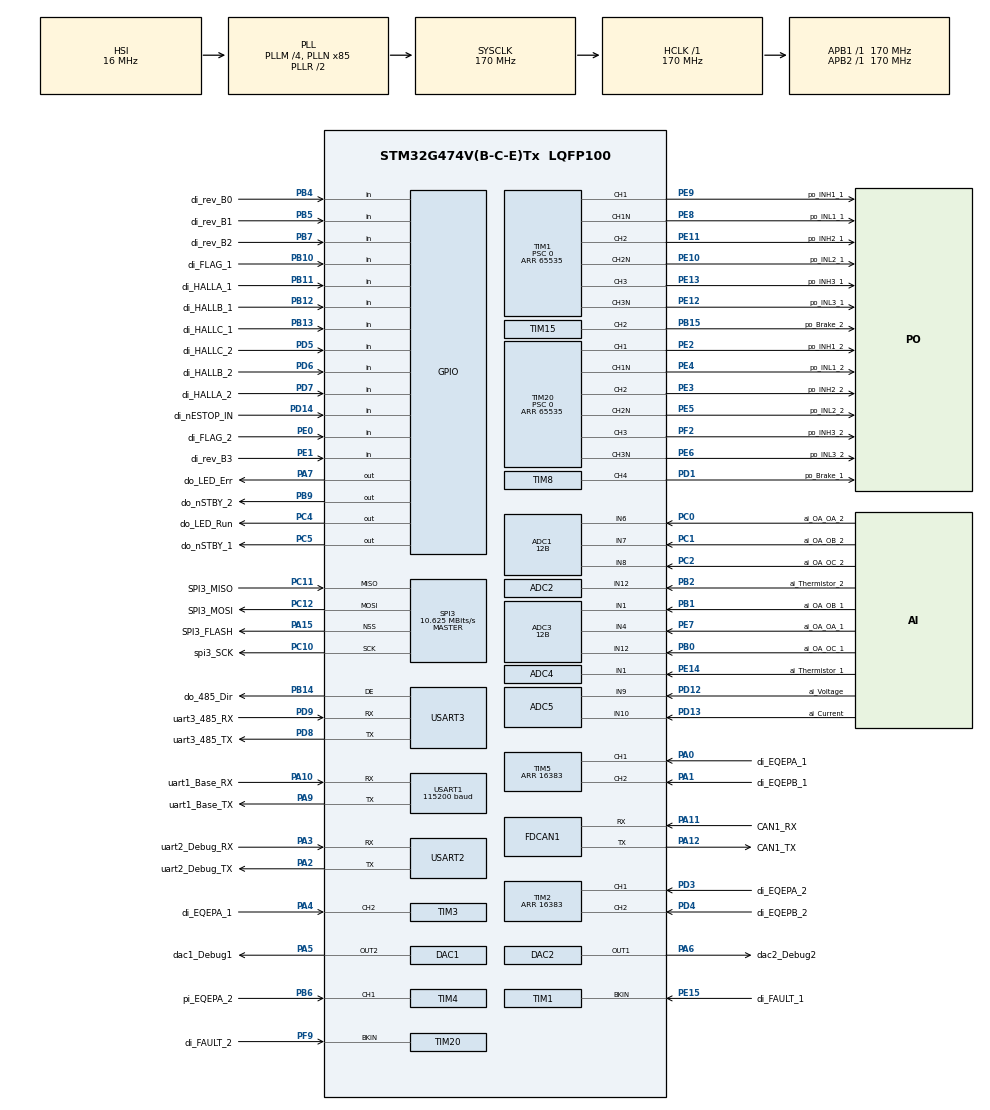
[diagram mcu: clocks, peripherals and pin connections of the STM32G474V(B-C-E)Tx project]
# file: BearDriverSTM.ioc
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ADC1.ClockPrescaler=ADC_CLOCK_ASYNC_DIV4
ADC1.ContinuousConvMode=DISABLE
ADC1.DMAContinuousRequests=DISABLE
ADC1.DataAlign=ADC_DATAALIGN_RIGHT
ADC1.DiscontinuousConvMode=DISABLE
ADC1.EOCSelection=ADC_EOC_SINGLE_CONV
ADC1.EnableAnalogWatchDog1=false
ADC1.EnableAnalogWatchDog2=false
ADC1.EnableAnalogWatchDog3=false
ADC1.EnableInjectedConversion=ENABLE
ADC1.EnableRegularConversion=DISABLE
ADC1.ExternalTrigInjecConv=ADC_EXTERNALTRIGINJEC_T1_TRGO
ADC1.ExternalTrigInjecConvEdge=ADC_EXTERNALTRIGINJECCONV_EDGE_RISING
ADC1.InjNumberOfConversion=2
ADC1.InjectedChannel-1\#ChannelInjectedConversion=ADC_CHANNEL_6
ADC1.InjectedChannel-2\#ChannelInjectedConversion=ADC_CHANNEL_7
ADC1.InjectedConvMode=None
ADC1.InjectedOffset-1\#ChannelInjectedConversion=0
ADC1.InjectedOffset-2\#ChannelInjectedConversion=0
ADC1.InjectedOffsetNumber-1\#ChannelInjectedConversion=ADC_OFFSET_NONE
ADC1.InjectedOffsetNumber-2\#ChannelInjectedConversion=ADC_OFFSET_NONE
ADC1.InjectedRank-1\#ChannelInjectedConversion=1
ADC1.InjectedRank-2\#ChannelInjectedConversion=2
ADC1.InjectedSamplingTime-1\#ChannelInjectedConversion=ADC_SAMPLETIME_6CYCLES_5
ADC1.InjectedSamplingTime-2\#ChannelInjectedConversion=ADC_SAMPLETIME_6CYCLES_5
ADC1.LowPowerAutoWait=DISABLE
ADC1.Overrun=ADC_OVR_DATA_PRESERVED
ADC1.Resolution=ADC_RESOLUTION_12B
ADC1.ScanConvMode=ADC_SCAN_ENABLE
ADC1.master=1
ADC2.Channel-0\#ChannelRegularConversion=ADC_CHANNEL_12
ADC2.ClockPrescaler=ADC_CLOCK_ASYNC_DIV4
ADC2.ContinuousConvMode=DISABLE
ADC2.DMAContinuousRequests=DISABLE
ADC2.DataAlign=ADC_DATAALIGN_RIGHT
ADC2.DiscontinuousConvMode=DISABLE
ADC2.EOCSelection=ADC_EOC_SINGLE_CONV
ADC2.EnableAnalogWatchDog1=false
ADC2.EnableAnalogWatchDog2=false
ADC2.EnableAnalogWatchDog3=false
ADC2.EnableInjectedConversion=ENABLE
ADC2.EnableRegularConversion=ENABLE
ADC2.ExternalTrigConv=ADC_SOFTWARE_START
ADC2.ExternalTrigConvEdge=ADC_EXTERNALTRIGCONVEDGE_NONE
ADC2.ExternalTrigInjecConv=ADC_EXTERNALTRIGINJEC_T1_TRGO
ADC2.ExternalTrigInjecConvEdge=ADC_EXTERNALTRIGINJECCONV_EDGE_RISING
ADC2.InjNumberOfConversion=1
ADC2.InjectedChannel-1\#ChannelInjectedConversion=ADC_CHANNEL_12
ADC2.InjectedConvMode=None
ADC2.InjectedOffset-1\#ChannelInjectedConversion=0
ADC2.InjectedOffsetNumber-1\#ChannelInjectedConversion=ADC_OFFSET_NONE
ADC2.InjectedRank-1\#ChannelInjectedConversion=1
ADC2.InjectedSamplingTime-1\#ChannelInjectedConversion=ADC_SAMPLETIME_6CYCLES_5
ADC2.LowPowerAutoWait=DISABLE
ADC2.NbrOfConversion=1
ADC2.OffsetNumber-0\#ChannelRegularConversion=ADC_OFFSET_NONE
ADC2.Overrun=ADC_OVR_DATA_PRESERVED
ADC2.Rank-0\#ChannelRegularConversion=1
ADC2.Resolution=ADC_RESOLUTION_12B
ADC2.SamplingTime-0\#ChannelRegularConversion=ADC_SAMPLETIME_47CYCLES_5
ADC2.ScanConvMode=ADC_SCAN_DISABLE
ADC2.master=1
ADC3.ClockPrescaler=ADC_CLOCK_ASYNC_DIV4
ADC3.ContinuousConvMode=DISABLE
ADC3.DMAContinuousRequests=DISABLE
ADC3.DataAlign=ADC_DATAALIGN_RIGHT
ADC3.DiscontinuousConvMode=DISABLE
ADC3.EOCSelection=ADC_EOC_SINGLE_CONV
ADC3.EnableAnalogWatchDog1=false
ADC3.EnableAnalogWatchDog2=false
ADC3.EnableAnalogWatchDog3=false
ADC3.EnableInjectedConversion=ENABLE
ADC3.EnableRegularConversion=DISABLE
ADC3.ExternalTrigInjecConv=ADC_EXTERNALTRIGINJEC_T20_TRGO
ADC3.ExternalTrigInjecConvEdge=ADC_EXTERNALTRIGINJECCONV_EDGE_RISING
ADC3.InjNumberOfConversion=2
ADC3.InjectedChannel-1\#ChannelInjectedConversion=ADC_CHANNEL_4
ADC3.InjectedChannel-2\#ChannelInjectedConversion=ADC_CHANNEL_12
ADC3.InjectedConvMode=None
ADC3.InjectedOffset-1\#ChannelInjectedConversion=0
ADC3.InjectedOffset-2\#ChannelInjectedConversion=0
ADC3.InjectedOffsetNumber-1\#ChannelInjectedConversion=ADC_OFFSET_NONE
ADC3.InjectedOffsetNumber-2\#ChannelInjectedConversion=ADC_OFFSET_NONE
ADC3.InjectedRank-1\#ChannelInjectedConversion=1
ADC3.InjectedRank-2\#ChannelInjectedConversion=2
ADC3.InjectedSamplingTime-1\#ChannelInjectedConversion=ADC_SAMPLETIME_6CYCLES_5
ADC3.InjectedSamplingTime-2\#ChannelInjectedConversion=ADC_SAMPLETIME_6CYCLES_5
ADC3.LowPowerAutoWait=DISABLE
ADC3.Overrun=ADC_OVR_DATA_PRESERVED
ADC3.Resolution=ADC_RESOLUTION_12B
ADC3.ScanConvMode=ADC_SCAN_ENABLE
ADC3.master=1
ADC4.Channel-2\#ChannelRegularConversion=ADC_CHANNEL_1
ADC4.ClockPrescaler=ADC_CLOCK_ASYNC_DIV4
ADC4.ContinuousConvMode=DISABLE
ADC4.DMAContinuousRequests=DISABLE
ADC4.DataAlign=ADC_DATAALIGN_RIGHT
ADC4.DiscontinuousConvMode=DISABLE
ADC4.EOCSelection=ADC_EOC_SINGLE_CONV
ADC4.EnableInjectedConversion=DISABLE
ADC4.EnableRegularConversion=ENABLE
ADC4.LowPowerAutoWait=DISABLE
ADC4.NbrOfConversionFlag=1
ADC4.OffsetNumber-2\#ChannelRegularConversion=ADC_OFFSET_NONE
ADC4.Overrun=ADC_OVR_DATA_PRESERVED
ADC4.Rank-2\#ChannelRegularConversion=1
ADC4.Resolution=ADC_RESOLUTION_12B
ADC4.SamplingTime-2\#ChannelRegularConversion=ADC_SAMPLETIME_2CYCLES_5
ADC4.ScanConvMode=ADC_SCAN_DISABLE
ADC5.Channel-0\#ChannelRegularConversion=ADC_CHANNEL_9
ADC5.Channel-1\#ChannelRegularConversion=ADC_CHANNEL_10
ADC5.ClockPrescaler=ADC_CLOCK_ASYNC_DIV4
ADC5.ContinuousConvMode=DISABLE
ADC5.EOCSelection=ADC_EOC_SINGLE_CONV
ADC5.EnableRegularConversion=ENABLE
ADC5.NbrOfConversion=2
ADC5.OffsetNumber-0\#ChannelRegularConversion=ADC_OFFSET_NONE
ADC5.OffsetNumber-1\#ChannelRegularConversion=ADC_OFFSET_NONE
ADC5.Rank-0\#ChannelRegularConversion=1
ADC5.Rank-1\#ChannelRegularConversion=2
ADC5.SamplingTime-0\#ChannelRegularConversion=ADC_SAMPLETIME_47CYCLES_5
ADC5.SamplingTime-1\#ChannelRegularConversion=ADC_SAMPLETIME_47CYCLES_5
ADC5.ScanConvMode=ADC_SCAN_ENABLE
DAC1.DAC_Channel-DAC_OUT2=DAC_CHANNEL_2
DAC2.DAC_OutputBuffer=DAC_OUTPUTBUFFER_DISABLE
DAC2.DAC_Trigger=DAC_TRIGGER_SOFTWARE
FDCAN1.CalculateBaudRateNominal=3541666
FDCAN1.CalculateTimeBitNominal=282
FDCAN1.CalculateTimeQuantumNominal=94.11764705882354
IWDG.Prescaler=IWDG_PRESCALER_4
Mcu.Family=STM32G4
Mcu.Name=STM32G474V(B-C-E)Tx
Mcu.Package=LQFP100
NVIC.ADC1_2_IRQn=true\:2\:0\:true\:true\:true\:5\:true\:true\:true
NVIC.ADC3_IRQn=true\:2\:0\:true\:true\:true\:9\:true\:true\:true
NVIC.PriorityGroup=NVIC_PRIORITYGROUP_3
NVIC.TIM1_BRK_TIM15_IRQn=true\:4\:0\:true\:true\:true\:3\:true\:true\:true
NVIC.TIM1_UP_TIM16_IRQn=true\:0\:0\:false\:true\:true\:4\:true\:true\:true
NVIC.TIM20_BRK_IRQn=true\:4\:0\:true\:true\:true\:10\:true\:true\:true
NVIC.TIM20_UP_IRQn=true\:0\:0\:false\:true\:true\:11\:true\:true\:true
NVIC.TIM2_IRQn=true\:3\:0\:true\:true\:true\:6\:true\:true\:true
NVIC.TIM5_IRQn=true\:3\:0\:true\:true\:true\:12\:true\:true\:true
NVIC.USART1_IRQn=true\:3\:0\:true\:true\:true\:13\:true\:true\:true
NVIC.USART2_IRQn=true\:3\:0\:true\:true\:true\:1\:true\:true\:true
NVIC.USART3_IRQn=true\:3\:0\:true\:true\:true\:8\:true\:true\:true
PA0.GPIO_Label=di_EQEPA_1
PA0.Signal=S_TIM5_CH1
PA1.GPIO_Label=di_EQEPB_1
PA1.Signal=S_TIM5_CH2
PA10.GPIO_Label=uart1_Base_RX
PA10.Mode=Asynchronous
PA10.Signal=USART1_RX
PA11.GPIO_Label=CAN1_RX
PA11.Mode=FDCAN_Activate
PA11.Signal=FDCAN1_RX
PA12.GPIO_Label=CAN1_TX
PA12.Mode=FDCAN_Activate
PA12.Signal=FDCAN1_TX
PA13.GPIO_Label=SWDIO
PA13.Mode=Trace_Asynchronous_SW
PA13.Signal=SYS_JTMS-SWDIO
PA14.GPIO_Label=SWCLK
PA14.Mode=Trace_Asynchronous_SW
PA14.Signal=SYS_JTCK-SWCLK
PA15.GPIO_Label=SPI3_FLASH
PA15.Mode=NSS_Signal_Hard_Output
PA15.Signal=SPI3_NSS
PA2.GPIO_Label=uart2_Debug_TX
PA2.GPIO_PuPd=GPIO_PULLUP
PA2.GPIO_Speed=GPIO_SPEED_FREQ_HIGH
PA2.Mode=Asynchronous
PA2.Signal=USART2_TX
PA3.GPIO_Label=uart2_Debug_RX
PA3.GPIO_PuPd=GPIO_PULLUP
PA3.GPIO_Speed=GPIO_SPEED_FREQ_HIGH
PA3.Mode=Asynchronous
PA3.Signal=USART2_RX
PA4.GPIO_Label=di_EQEPA_1
PA4.Signal=S_TIM3_CH2
PA5.GPIO_Label=dac1_Debug1
PA5.Signal=COMP_DAC12_group
PA6.GPIO_Label=dac2_Debug2
PA6.Signal=COMP_DAC21_group
PA7.GPIO_Label=do_LED_Err
PA7.Signal=GPIO_Output
PA9.GPIO_Label=uart1_Base_TX
PA9.Mode=Asynchronous
PA9.Signal=USART1_TX
PB0.GPIO_Label=ai_OA_OC_1
PB0.Mode=IN12-Single-Ended
PB0.Signal=ADC3_IN12
PB1.GPIO_Label=ai_OA_OB_1
PB1.Mode=IN1-Single-Ended
PB1.Signal=ADC3_IN1
PB10.GPIO_Label=di_FLAG_1
PB10.GPIO_PuPd=GPIO_PULLUP
PB10.Signal=GPIO_Input
PB11.GPIO_Label=di_HALLA_1
PB11.Signal=GPIO_Input
PB12.GPIO_Label=di_HALLB_1
PB12.Signal=GPIO_Input
PB13.GPIO_Label=di_HALLC_1
PB13.Signal=GPIO_Input
PB14.GPIO_Label=do_485_Dir
PB14.Mode=Hardware Flow Control (RS485)
PB14.Signal=USART3_DE
PB15.GPIO_Label=po_Brake_2
PB15.GPIO_PuPd=GPIO_PULLDOWN
PB15.GPIO_Speed=GPIO_SPEED_FREQ_HIGH
PB15.Signal=S_TIM15_CH2
PB2.GPIO_Label=ai_Thermistor_2
PB2.Mode=IN12-Single-Ended
PB2.Signal=ADC2_IN12
PB3.GPIO_Label=SWO
PB3.Mode=Trace_Asynchronous_SW
PB3.Signal=SYS_JTDO-SWO
PB4.GPIO_Label=di_rev_B0
PB4.Signal=GPIO_Input
PB5.GPIO_Label=di_rev_B1
PB5.Signal=GPIO_Input
PB6.GPIO_Label=pi_EQEPA_2
PB6.Signal=S_TIM4_CH1
PB7.GPIO_Label=di_rev_B2
PB7.Signal=GPIO_Input
PB9.GPIO_Label=do_nSTBY_2
PB9.Signal=GPIO_Output
PC0.GPIO_Label=ai_OA_OA_2
PC0.Mode=IN6-Single-Ended
PC0.Signal=ADC1_IN6
PC1.GPIO_Label=ai_OA_OB_2
PC1.Mode=IN7-Single-Ended
PC1.Signal=ADC1_IN7
PC10.GPIO_Label=spi3_SCK
PC10.Mode=Full_Duplex_Master
PC10.Signal=SPI3_SCK
PC11.GPIO_Label=SPI3_MISO
PC11.Mode=Full_Duplex_Master
PC11.Signal=SPI3_MISO
PC12.GPIO_Label=SPI3_MOSI
PC12.Mode=Full_Duplex_Master
PC12.Signal=SPI3_MOSI
PC2.GPIO_Label=ai_OA_OC_2
PC2.Mode=IN8-Single-Ended
PC2.Signal=ADC1_IN8
PC4.GPIO_Label=do_LED_Run
PC4.Signal=GPIO_Output
PC5.GPIO_Label=do_nSTBY_1
PC5.Signal=GPIO_Output
PD1.GPIO_Label=po_Brake_1
PD1.GPIO_PuPd=GPIO_PULLDOWN
PD1.GPIO_Speed=GPIO_SPEED_FREQ_HIGH
PD1.Signal=S_TIM8_CH4
PD12.GPIO_Label=ai_Voltage
PD12.Mode=IN9-Single-Ended
PD12.Signal=ADC5_IN9
PD13.GPIO_Label=ai_Current
PD13.Mode=IN10-Single-Ended
PD13.Signal=ADC5_IN10
PD14.GPIO_Label=di_nESTOP_IN
PD14.Signal=GPIO_Input
PD3.GPIO_Label=di_EQEPA_2
PD3.Signal=S_TIM2_CH1
PD4.GPIO_Label=di_EQEPB_2
PD4.Signal=S_TIM2_CH2
PD5.GPIO_Label=di_HALLC_2
PD5.Signal=GPIO_Input
PD6.GPIO_Label=di_HALLB_2
PD6.Signal=GPIO_Input
PD7.GPIO_Label=di_HALLA_2
PD7.Signal=GPIO_Input
PD8.GPIO_Label=uart3_485_TX
PD8.Mode=Asynchronous
PD8.Signal=USART3_TX
PD9.GPIO_Label=uart3_485_RX
PD9.Mode=Asynchronous
PD9.Signal=USART3_RX
PE0.GPIO_Label=di_FLAG_2
PE0.GPIO_PuPd=GPIO_PULLUP
PE0.Signal=GPIO_Input
PE1.GPIO_Label=di_rev_B3
PE1.Signal=GPIO_Input
PE10.GPIO_Label=po_INL2_1
PE10.GPIO_PuPd=GPIO_PULLDOWN
PE10.GPIO_Speed=GPIO_SPEED_FREQ_HIGH
PE10.Mode=PWM Generation2 CH2 CH2N
PE10.Signal=TIM1_CH2N
PE11.GPIO_Label=po_INH2_1
PE11.GPIO_ModeDefaultPP=GPIO_MODE_AF_PP
PE11.GPIO_PuPd=GPIO_PULLDOWN
PE11.GPIO_Speed=GPIO_SPEED_FREQ_HIGH
PE11.Signal=S_TIM1_CH2
PE12.GPIO_Label=po_INL3_1
PE12.GPIO_ModeDefaultPP=GPIO_MODE_AF_PP
PE12.GPIO_PuPd=GPIO_PULLDOWN
PE12.GPIO_Speed=GPIO_SPEED_FREQ_HIGH
PE12.Mode=PWM Generation3 CH3 CH3N
PE12.Signal=TIM1_CH3N
PE13.GPIO_Label=po_INH3_1
PE13.GPIO_PuPd=GPIO_PULLDOWN
PE13.GPIO_Speed=GPIO_SPEED_FREQ_HIGH
PE13.Signal=S_TIM1_CH3
PE14.GPIO_Label=ai_Thermistor_1
PE14.Mode=IN1-Single-Ended
PE14.Signal=ADC4_IN1
PE15.GPIO_Label=di_FAULT_1
PE15.GPIO_PuPd=GPIO_PULLUP
PE15.Mode=Activate-Break-Input
PE15.Signal=TIM1_BKIN
PE2.GPIO_Label=po_INH1_2
PE2.GPIO_PuPd=GPIO_PULLDOWN
PE2.GPIO_Speed=GPIO_SPEED_FREQ_HIGH
PE2.Signal=S_TIM20_CH1
PE3.GPIO_Label=po_INH2_2
PE3.GPIO_PuPd=GPIO_PULLDOWN
PE3.GPIO_Speed=GPIO_SPEED_FREQ_HIGH
PE3.Signal=S_TIM20_CH2
PE4.GPIO_Label=po_INL1_2
PE4.GPIO_PuPd=GPIO_PULLDOWN
PE4.GPIO_Speed=GPIO_SPEED_FREQ_HIGH
PE4.Mode=PWM Generation1 CH1 CH1N
PE4.Signal=TIM20_CH1N
PE5.GPIO_Label=po_INL2_2
PE5.GPIO_PuPd=GPIO_PULLDOWN
PE5.GPIO_Speed=GPIO_SPEED_FREQ_HIGH
PE5.Mode=PWM Generation2 CH2 CH2N
PE5.Signal=TIM20_CH2N
PE6.GPIO_Label=po_INL3_2
PE6.GPIO_PuPd=GPIO_PULLDOWN
PE6.GPIO_Speed=GPIO_SPEED_FREQ_HIGH
PE6.Mode=PWM Generation3 CH3 CH3N
PE6.Signal=TIM20_CH3N
PE7.GPIO_Label=ai_OA_OA_1
PE7.Mode=IN4-Single-Ended
PE7.Signal=ADC3_IN4
PE8.GPIO_Label=po_INL1_1
PE8.GPIO_ModeDefaultPP=GPIO_MODE_AF_PP
PE8.GPIO_PuPd=GPIO_PULLDOWN
PE8.GPIO_Speed=GPIO_SPEED_FREQ_HIGH
PE8.Mode=PWM Generation1 CH1 CH1N
PE8.Signal=TIM1_CH1N
PE9.GPIO_Label=po_INH1_1
PE9.GPIO_ModeDefaultPP=GPIO_MODE_AF_PP
PE9.GPIO_PuPd=GPIO_PULLDOWN
PE9.GPIO_Speed=GPIO_SPEED_FREQ_HIGH
PE9.Signal=S_TIM1_CH1
PF0-OSC_IN.Mode=HSE-External-Oscillator
PF0-OSC_IN.Signal=RCC_OSC_IN
PF1-OSC_OUT.Mode=HSE-External-Oscillator
PF1-OSC_OUT.Signal=RCC_OSC_OUT
PF2.GPIO_Label=po_INH3_2
PF2.GPIO_PuPd=GPIO_PULLDOWN
PF2.GPIO_Speed=GPIO_SPEED_FREQ_HIGH
PF2.Signal=S_TIM20_CH3
PF9.GPIO_Label=di_FAULT_2
PF9.GPIO_PuPd=GPIO_PULLUP
PF9.Mode=Activate-Break-Input
PF9.Signal=TIM20_BKIN
ProjectManager.HeapSize=0x200
ProjectManager.StackSize=0x400
ProjectManager.TargetToolchain=STM32CubeIDE
RCC.ADC12CLockSelection=RCC_ADC12CLKSOURCE_PLL
RCC.ADC12Freq_Value=170000000
RCC.ADC345Freq_Value=170000000
RCC.AHBFreq_Value=170000000
RCC.APB1Freq_Value=170000000
RCC.APB1TimFreq_Value=170000000
RCC.APB2Freq_Value=170000000
RCC.APB2TimFreq_Value=170000000
RCC.CortexFreq_Value=170000000
RCC.EXTERNAL_CLOCK_VALUE=12288000
RCC.HCLKFreq_Value=170000000
RCC.HSE_VALUE=8000000
RCC.HSI48_VALUE=48000000
RCC.HSI_VALUE=16000000
RCC.LSE_VALUE=32768
RCC.PLLM=RCC_PLLM_DIV4
RCC.PLLN=85
RCC.SYSCLKFreq_VALUE=170000000
RCC.SYSCLKSource=RCC_SYSCLKSOURCE_PLLCLK
RCC.USBFreq_Value=170000000
RCC.VCOOutputFreq_Value=340000000
SH.COMP_DAC12_group.0=DAC1_OUT2,DAC_OUT2
SH.COMP_DAC21_group.0=DAC2_OUT1,DAC_OUT1
SH.S_TIM15_CH2.0=TIM15_CH2,PWM Generation2 CH2
SH.S_TIM1_CH1.0=TIM1_CH1,PWM Generation1 CH1 CH1N
SH.S_TIM1_CH2.0=TIM1_CH2,PWM Generation2 CH2 CH2N
SH.S_TIM1_CH3.0=TIM1_CH3,PWM Generation3 CH3 CH3N
SH.S_TIM20_CH1.0=TIM20_CH1,PWM Generation1 CH1 CH1N
SH.S_TIM20_CH2.0=TIM20_CH2,PWM Generation2 CH2 CH2N
SH.S_TIM20_CH3.0=TIM20_CH3,PWM Generation3 CH3 CH3N
SH.S_TIM2_CH1.0=TIM2_CH1,Encoder_Interface
SH.S_TIM2_CH2.0=TIM2_CH2,Encoder_Interface
SH.S_TIM3_CH2.0=TIM3_CH2,Input_Capture2_from_TI2
SH.S_TIM4_CH1.0=TIM4_CH1,Input_Capture1_from_TI1
SH.S_TIM5_CH1.0=TIM5_CH1,Encoder_Interface
SH.S_TIM5_CH2.0=TIM5_CH2,Encoder_Interface
SH.S_TIM8_CH4.0=TIM8_CH4,PWM Generation4 CH4
SPI3.BaudRatePrescaler=SPI_BAUDRATEPRESCALER_16
SPI3.CalculateBaudRate=10.625 MBits/s
SPI3.DataSize=SPI_DATASIZE_8BIT
SPI3.Direction=SPI_DIRECTION_2LINES
SPI3.Mode=SPI_MODE_MASTER
SPI3.VirtualNSS=VM_NSSHARD
SPI3.VirtualType=VM_MASTER
TIM1.AutoReloadPreload=TIM_AUTORELOAD_PRELOAD_DISABLE
TIM1.AutomaticOutput=TIM_AUTOMATICOUTPUT_DISABLE
TIM1.Break2Filter=3
TIM1.Break2Polarity=TIM_BREAK2POLARITY_HIGH
TIM1.Break2State=TIM_BREAK2_DISABLE
TIM1.BreakFilter=3
TIM1.BreakPolarity=TIM_BREAKPOLARITY_LOW
TIM1.BreakState=TIM_BREAK_ENABLE
TIM1.Channel=TIM_CHANNEL_4
TIM1.Channel-PWM\ Generation1\ CH1\ CH1N=TIM_CHANNEL_1
TIM1.Channel-PWM\ Generation2\ CH2\ CH2N=TIM_CHANNEL_2
TIM1.Channel-PWM\ Generation3\ CH3\ CH3N=TIM_CHANNEL_3
TIM1.Channel-PWM\ Generation4\ No\ Output=TIM_CHANNEL_4
TIM1.ClearInputSource=TIM_CLEARINPUTSOURCE_NONE
TIM1.ClockDivision=TIM_CLOCKDIVISION_DIV2
TIM1.CounterMode=TIM_COUNTERMODE_CENTERALIGNED1
TIM1.DeadTime=0
TIM1.LockLevel=TIM_LOCKLEVEL_OFF
TIM1.OC1Preload_PWM=ENABLE
TIM1.OC2Preload_PWM=ENABLE
TIM1.OC3Preload_PWM=ENABLE
TIM1.OC4Preload_PWM=ENABLE
TIM1.OCFastMode_PWM=TIM_OCFAST_DISABLE
TIM1.OCIdleState_1=TIM_OCIDLESTATE_RESET
TIM1.OCIdleState_2=TIM_OCIDLESTATE_RESET
TIM1.OCIdleState_3=TIM_OCIDLESTATE_RESET
TIM1.OCIdleState_4=TIM_OCIDLESTATE_RESET
TIM1.OCMode_PWM-PWM\ Generation1\ CH1\ CH1N=TIM_OCMODE_PWM1
TIM1.OCMode_PWM-PWM\ Generation2\ CH2\ CH2N=TIM_OCMODE_PWM1
TIM1.OCMode_PWM-PWM\ Generation3\ CH3\ CH3N=TIM_OCMODE_PWM1
TIM1.OCMode_PWM-PWM\ Generation4\ No\ Output=TIM_OCMODE_PWM2
TIM1.OCNIdleState_1=TIM_OCNIDLESTATE_RESET
TIM1.OCNIdleState_2=TIM_OCNIDLESTATE_RESET
TIM1.OCNIdleState_3=TIM_OCNIDLESTATE_RESET
TIM1.OCNPolarity_1=TIM_OCNPOLARITY_HIGH
TIM1.OCNPolarity_2=TIM_OCNPOLARITY_HIGH
TIM1.OCNPolarity_3=TIM_OCNPOLARITY_HIGH
TIM1.OCPolarity_1=TIM_OCPOLARITY_HIGH
TIM1.OCPolarity_2=TIM_OCPOLARITY_HIGH
TIM1.OCPolarity_3=TIM_OCPOLARITY_HIGH
TIM1.OCPolarity_4=TIM_OCPOLARITY_HIGH
TIM1.OffStateIDLEMode=TIM_OSSI_ENABLE
TIM1.OffStateRunMode=TIM_OSSR_ENABLE
TIM1.PeriodNoDither=65535
TIM1.Prescaler=0
TIM1.PulseNoDither_1=0
TIM1.PulseNoDither_2=0
TIM1.PulseNoDither_3=0
TIM1.PulseNoDither_4=0
TIM1.RepetitionCounter=0
TIM1.SourceBRK2DigInput=TIM_BREAKINPUTSOURCE_DISABLE
TIM1.SourceBRKDigInput=TIM_BREAKINPUTSOURCE_ENABLE
TIM1.SourceBRKDigInputPolarity=TIM_BREAKINPUTSOURCE_POLARITY_LOW
TIM1.TIM_MasterOutputTrigger=TIM_TRGO_OC4REF
TIM1.TIM_MasterOutputTrigger2=TIM_TRGO2_RESET
TIM1.TIM_MasterSlaveMode=TIM_MASTERSLAVEMODE_DISABLE
TIM1.TIM_SlaveMode=TIM_SLAVEMODE_TRIGGER
TIM15.Channel-PWM\ Generation2\ CH2=TIM_CHANNEL_2
TIM2.EncoderMode=TIM_ENCODERMODE_TI12
TIM2.IC1Filter=0
TIM2.IC1Polarity=TIM_ICPOLARITY_RISING
TIM2.IC2Filter=0
TIM2.IC2Polarity=TIM_ICPOLARITY_RISING
TIM2.PeriodNoDither=16383
TIM20.AutoReloadPreload=TIM_AUTORELOAD_PRELOAD_DISABLE
TIM20.AutomaticOutput=TIM_AUTOMATICOUTPUT_DISABLE
TIM20.Break2Filter=3
TIM20.Break2Polarity=TIM_BREAK2POLARITY_HIGH
TIM20.Break2State=TIM_BREAK2_DISABLE
TIM20.BreakFilter=3
TIM20.BreakPolarity=TIM_BREAKPOLARITY_LOW
TIM20.BreakState=TIM_BREAK_ENABLE
TIM20.Channel=TIM_CHANNEL_4
TIM20.Channel-PWM\ Generation1\ CH1\ CH1N=TIM_CHANNEL_1
TIM20.Channel-PWM\ Generation2\ CH2\ CH2N=TIM_CHANNEL_2
TIM20.Channel-PWM\ Generation3\ CH3\ CH3N=TIM_CHANNEL_3
TIM20.Channel-PWM\ Generation4\ No\ Output=TIM_CHANNEL_4
TIM20.ClearInputSource=TIM_CLEARINPUTSOURCE_NONE
TIM20.ClockDivision=TIM_CLOCKDIVISION_DIV2
TIM20.CounterMode=TIM_COUNTERMODE_CENTERALIGNED1
TIM20.DeadTime=0
TIM20.LockLevel=TIM_LOCKLEVEL_OFF
TIM20.OC1Preload_PWM=ENABLE
TIM20.OC2Preload_PWM=ENABLE
TIM20.OC3Preload_PWM=ENABLE
TIM20.OC4Preload_PWM=ENABLE
TIM20.OCFastMode_PWM=TIM_OCFAST_DISABLE
TIM20.OCIdleState_1=TIM_OCIDLESTATE_RESET
TIM20.OCIdleState_2=TIM_OCIDLESTATE_RESET
TIM20.OCIdleState_3=TIM_OCIDLESTATE_RESET
TIM20.OCIdleState_4=TIM_OCIDLESTATE_RESET
TIM20.OCMode_PWM-PWM\ Generation1\ CH1\ CH1N=TIM_OCMODE_PWM1
TIM20.OCMode_PWM-PWM\ Generation2\ CH2\ CH2N=TIM_OCMODE_PWM1
TIM20.OCMode_PWM-PWM\ Generation3\ CH3\ CH3N=TIM_OCMODE_PWM1
TIM20.OCMode_PWM-PWM\ Generation4\ No\ Output=TIM_OCMODE_PWM2
TIM20.OCNIdleState_1=TIM_OCNIDLESTATE_RESET
TIM20.OCNIdleState_2=TIM_OCNIDLESTATE_RESET
TIM20.OCNIdleState_3=TIM_OCNIDLESTATE_RESET
TIM20.OCNPolarity_1=TIM_OCNPOLARITY_HIGH
TIM20.OCNPolarity_2=TIM_OCNPOLARITY_HIGH
TIM20.OCNPolarity_3=TIM_OCNPOLARITY_HIGH
TIM20.OCPolarity_1=TIM_OCPOLARITY_HIGH
TIM20.OCPolarity_2=TIM_OCPOLARITY_HIGH
TIM20.OCPolarity_3=TIM_OCPOLARITY_HIGH
TIM20.OCPolarity_4=TIM_OCPOLARITY_HIGH
TIM20.OffStateIDLEMode=TIM_OSSI_ENABLE
TIM20.OffStateRunMode=TIM_OSSR_ENABLE
TIM20.PeriodNoDither=65535
TIM20.Prescaler=0
TIM20.PulseNoDither_1=0
TIM20.PulseNoDither_2=0
TIM20.PulseNoDither_3=0
TIM20.PulseNoDither_4=0
TIM20.RepetitionCounter=0
TIM20.SourceBRK2DigInput=TIM_BREAKINPUTSOURCE_DISABLE
TIM20.SourceBRKDigInput=TIM_BREAKINPUTSOURCE_ENABLE
TIM20.SourceBRKDigInputPolarity=TIM_BREAKINPUTSOURCE_POLARITY_LOW
TIM20.TIM_MasterOutputTrigger=TIM_TRGO_OC4REF
TIM20.TIM_MasterOutputTrigger2=TIM_TRGO2_RESET
TIM20.TIM_MasterSlaveMode=TIM_MASTERSLAVEMODE_DISABLE
TIM20.TIM_SlaveMode=TIM_SLAVEMODE_TRIGGER
TIM3.Channel-Input_Capture2_from_TI2=TIM_CHANNEL_2
TIM4.Channel-Input_Capture1_from_TI1=TIM_CHANNEL_1
TIM5.EncoderMode=TIM_ENCODERMODE_TI12
TIM5.IC1Filter=0
TIM5.IC1Polarity=TIM_ICPOLARITY_RISING
TIM5.IC2Filter=0
TIM5.IC2Polarity=TIM_ICPOLARITY_RISING
TIM5.PeriodNoDither=16383
TIM8.Channel-PWM\ Generation4\ CH4=TIM_CHANNEL_4
USART1.BaudRate=115200
USART1.VirtualMode-Asynchronous=VM_ASYNC
USART1.WordLength=WORDLENGTH_8B
USART2.VirtualMode-Asynchronous=VM_ASYNC
USART3.VirtualMode-Asynchronous=VM_ASYNC
USART3.VirtualMode-Hardware\ Flow\ Control\ (RS485)=VM_ASYNC
VP_IWDG_VS_IWDG.Mode=IWDG_Activate
VP_SYS_VS_DBSignals.Mode=DisableDeadBatterySignals
VP_TIM1_VS_no_output4.Mode=PWM Generation4 No Output
VP_TIM20_VS_no_output4.Mode=PWM Generation4 No Output
board=custom

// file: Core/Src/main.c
/* USER CODE BEGIN Header */
/**
  ******************************************************************************
  * @file           : main.c
  * @brief          : Main program body
  ******************************************************************************
  * @attention
  *
  * Copyright (c) 2026 STMicroelectronics.
  * All rights reserved.
  *
  * This software is licensed under terms that can be found in the LICENSE file
  * in the root directory of this software component.
  * If no LICENSE file comes with this software, it is provided AS-IS.
  *
  ******************************************************************************
  */
/* USER CODE END Header */
#include "main.h"
#include "adc.h"
#include "dac.h"
#include "fdcan.h"
#include "iwdg.h"
#include "spi.h"
#include "tim.h"
#include "usart.h"
#include "gpio.h"

/* USER CODE BEGIN Includes */
#include "bear_driver.h"
#include "debug.h"
/* USER CODE END Includes */

/* USER CODE BEGIN PV */
volatile uint32_t IdleLoopCount = 0;
/* USER CODE END PV */

void SystemClock_Config(void);
static void MX_NVIC_Init(void);

int main(void)
{

  /* MCU Configuration--------------------------------------------------------*/

  /* Reset of all peripherals, Initializes the Flash interface and the Systick. */
  HAL_Init();

  /* Configure the system clock */
  SystemClock_Config();

  /* Initialize all configured peripherals */
  MX_GPIO_Init();
  MX_ADC1_Init();
  MX_DAC1_Init();
  MX_DAC2_Init();
  MX_TIM1_Init();
  MX_TIM2_Init();
  MX_ADC3_Init();
  MX_ADC2_Init();
  MX_ADC4_Init();
  MX_TIM20_Init();
  MX_USART2_UART_Init();
  MX_ADC5_Init();
  MX_FDCAN1_Init();
  MX_SPI3_Init();
  MX_TIM5_Init();
  MX_USART1_UART_Init();
  MX_USART3_UART_Init();
  MX_TIM3_Init();
  MX_TIM4_Init();
  MX_TIM8_Init();
  MX_TIM15_Init();
  MX_IWDG_Init();

  /* Initialize interrupts */
  MX_NVIC_Init();
  /* USER CODE BEGIN 2 */
  Debug_Init();
  BearDriver_Main();  /* never returns — contains its own infinite loop */
  /* USER CODE END 2 */

  /* Infinite loop */
  while (1)
  {

  }
}

void SystemClock_Config(void)
{
  RCC_OscInitTypeDef RCC_OscInitStruct = {0};
  RCC_ClkInitTypeDef RCC_ClkInitStruct = {0};

  /** Configure the main internal regulator output voltage
  */
  HAL_PWREx_ControlVoltageScaling(PWR_REGULATOR_VOLTAGE_SCALE1_BOOST);

  /** Initializes the RCC Oscillators according to the specified parameters
  * in the RCC_OscInitTypeDef structure.
  */
  RCC_OscInitStruct.OscillatorType = RCC_OSCILLATORTYPE_HSI|RCC_OSCILLATORTYPE_LSI;
  RCC_OscInitStruct.HSIState = RCC_HSI_ON;
  RCC_OscInitStruct.HSICalibrationValue = RCC_HSICALIBRATION_DEFAULT;
  RCC_OscInitStruct.LSIState = RCC_LSI_ON;
  RCC_OscInitStruct.PLL.PLLState = RCC_PLL_ON;
  RCC_OscInitStruct.PLL.PLLSource = RCC_PLLSOURCE_HSI;
  RCC_OscInitStruct.PLL.PLLM = RCC_PLLM_DIV4;
  RCC_OscInitStruct.PLL.PLLN = 85;
  RCC_OscInitStruct.PLL.PLLP = RCC_PLLP_DIV2;
  RCC_OscInitStruct.PLL.PLLQ = RCC_PLLQ_DIV2;
  RCC_OscInitStruct.PLL.PLLR = RCC_PLLR_DIV2;
  if (HAL_RCC_OscConfig(&RCC_OscInitStruct) != HAL_OK)
  {
    Error_Handler();
  }

  /** Initializes the CPU, AHB and APB buses clocks
  */
  RCC_ClkInitStruct.ClockType = RCC_CLOCKTYPE_HCLK|RCC_CLOCKTYPE_SYSCLK
                              |RCC_CLOCKTYPE_PCLK1|RCC_CLOCKTYPE_PCLK2;
  RCC_ClkInitStruct.SYSCLKSource = RCC_SYSCLKSOURCE_PLLCLK;
  RCC_ClkInitStruct.AHBCLKDivider = RCC_SYSCLK_DIV1;
  RCC_ClkInitStruct.APB1CLKDivider = RCC_HCLK_DIV1;
  RCC_ClkInitStruct.APB2CLKDivider = RCC_HCLK_DIV1;

  if (HAL_RCC_ClockConfig(&RCC_ClkInitStruct, FLASH_LATENCY_4) != HAL_OK)
  {
    Error_Handler();
  }
}

/**
  * @brief NVIC Configuration.
  * @retval None
  */
static void MX_NVIC_Init(void)
{
  /* USART2_IRQn interrupt configuration */
  HAL_NVIC_SetPriority(USART2_IRQn, 3, 0);
  HAL_NVIC_EnableIRQ(USART2_IRQn);
  /* TIM1_BRK_TIM15_IRQn interrupt configuration */
  HAL_NVIC_SetPriority(TIM1_BRK_TIM15_IRQn, 4, 0);
  HAL_NVIC_EnableIRQ(TIM1_BRK_TIM15_IRQn);
  /* TIM1_UP_TIM16_IRQn interrupt configuration */
  HAL_NVIC_SetPriority(TIM1_UP_TIM16_IRQn, 0, 0);
  HAL_NVIC_EnableIRQ(TIM1_UP_TIM16_IRQn);
  /* ADC1_2_IRQn interrupt configuration */
  HAL_NVIC_SetPriority(ADC1_2_IRQn, 2, 0);
  HAL_NVIC_EnableIRQ(ADC1_2_IRQn);
  /* TIM2_IRQn interrupt configuration */
  HAL_NVIC_SetPriority(TIM2_IRQn, 3, 0);
  HAL_NVIC_EnableIRQ(TIM2_IRQn);
  /* USART3_IRQn interrupt configuration */
  HAL_NVIC_SetPriority(USART3_IRQn, 3, 0);
  HAL_NVIC_EnableIRQ(USART3_IRQn);
  /* ADC3_IRQn interrupt configuration */
  HAL_NVIC_SetPriority(ADC3_IRQn, 2, 0);
  HAL_NVIC_EnableIRQ(ADC3_IRQn);
  /* TIM20_BRK_IRQn interrupt configuration */
  HAL_NVIC_SetPriority(TIM20_BRK_IRQn, 4, 0);
  HAL_NVIC_EnableIRQ(TIM20_BRK_IRQn);
  /* TIM20_UP_IRQn interrupt configuration */
  HAL_NVIC_SetPriority(TIM20_UP_IRQn, 0, 0);
  HAL_NVIC_EnableIRQ(TIM20_UP_IRQn);
  /* TIM5_IRQn interrupt configuration */
  HAL_NVIC_SetPriority(TIM5_IRQn, 3, 0);
  HAL_NVIC_EnableIRQ(TIM5_IRQn);
  /* USART1_IRQn interrupt configuration */
  HAL_NVIC_SetPriority(USART1_IRQn, 3, 0);
  HAL_NVIC_EnableIRQ(USART1_IRQn);
}

void Error_Handler(void)
{
  __disable_irq();
  while (1)
  {
  }
}
